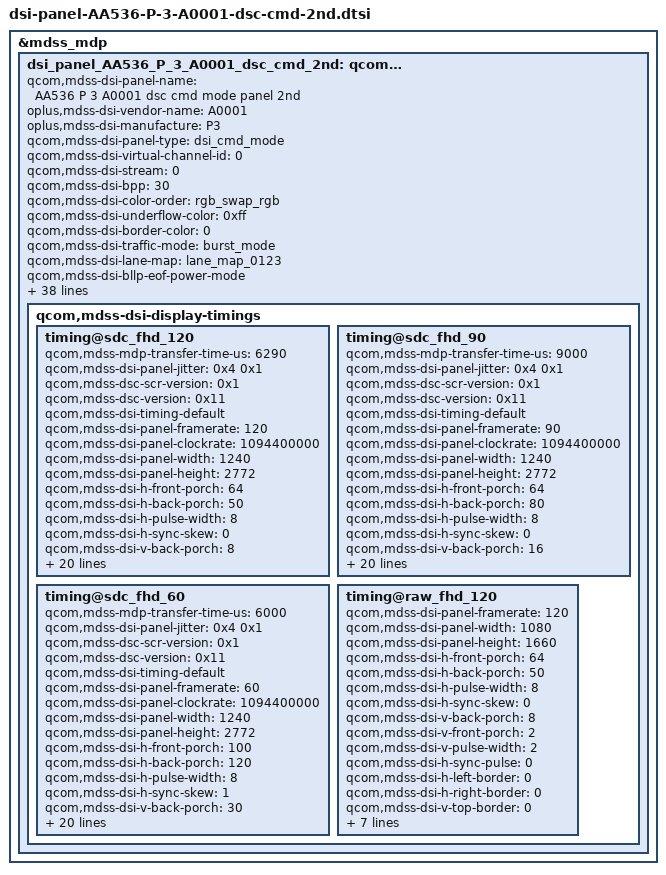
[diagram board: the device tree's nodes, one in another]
&mdss_mdp {
	dsi_panel_AA536_P_3_A0001_dsc_cmd_2nd: qcom,mdss_dsi_panel_AA536_P_3_A0001_dsc_cmd_2nd {
		qcom,mdss-dsi-panel-name = "AA536 P 3 A0001 dsc cmd mode panel 2nd";
		oplus,mdss-dsi-vendor-name = "A0001";
		oplus,mdss-dsi-manufacture = "P3";
		qcom,mdss-dsi-panel-type = "dsi_cmd_mode";
		qcom,mdss-dsi-virtual-channel-id = <0>;
		qcom,mdss-dsi-stream = <0>;
		qcom,mdss-dsi-bpp = <30>;
		qcom,mdss-dsi-color-order = "rgb_swap_rgb";
		qcom,mdss-dsi-underflow-color = <0xff>;
		qcom,mdss-dsi-border-color = <0>;
		//qcom,dsi-ctrl-num = <0>;
		//qcom,dsi-phy-num = <0>;
		qcom,mdss-dsi-traffic-mode = "burst_mode";
		qcom,mdss-dsi-lane-map = "lane_map_0123";
		qcom,mdss-dsi-bllp-eof-power-mode;
		qcom,mdss-dsi-bllp-power-mode;
		qcom,mdss-dsi-lane-0-state;
		qcom,mdss-dsi-lane-1-state;
		qcom,mdss-dsi-lane-2-state;
		qcom,mdss-dsi-lane-3-state;
		qcom,mdss-dsi-dma-trigger = "trigger_sw";
		qcom,mdss-loading-effect;
		qcom,mdss-dsi-mdp-trigger = "none";
		qcom,mdss-dsi-reset-sequence = <1 2>, <0 5>, <1 10>;
		qcom,mdss-dsi-te-pin-select = <1>;
		qcom,mdss-dsi-te-dcs-command = <1>;
		qcom,mdss-pan-physical-width-dimension = <70>;
		qcom,mdss-pan-physical-height-dimension = <155>;
		qcom,mdss-dsi-init-delay-us = <1000>;
		qcom,mdss-dsi-te-check-enable;
		qcom,mdss-dsi-te-using-te-pin;
		qcom,mdss-dsi-lp11-init;
		qcom,mdss-dsi-wr-mem-start = <0x2c>;
		qcom,mdss-dsi-wr-mem-continue = <0x3c>;
		qcom,mdss-dsi-panel-jitter = <0x4 0x1>;
		qcom,mdss-bl-high2bit;
		/* HDR Setting */
		qcom,mdss-dsi-panel-hdr-enabled;
		qcom,mdss-dsi-panel-hdr-color-primaries = <15635 16450 34000 16000 13250 34500 7500 3000>;
		qcom,mdss-dsi-panel-peak-brightness = <5400000>;
		qcom,mdss-dsi-panel-average-brightness = <2000000>;
		qcom,mdss-dsi-panel-blackness-level = <4000>;

		qcom,dynamic-mode-switch-enabled;
		qcom,dynamic-mode-switch-type = "dynamic-resolution-switch-immediate";
		qcom,mdss-dsi-display-timings {
			timing@sdc_fhd_120{
				qcom,mdss-mdp-transfer-time-us = <6290>;
				qcom,mdss-dsi-panel-jitter = <0x4 0x1>;
				qcom,mdss-dsc-scr-version = <0x1>;
				qcom,mdss-dsc-version = <0x11>;
				qcom,mdss-dsi-timing-default;
				qcom,mdss-dsi-panel-framerate = <120>;
				qcom,mdss-dsi-panel-clockrate = <1094400000>;
				qcom,mdss-dsi-panel-width = <1240>;
				qcom,mdss-dsi-panel-height = <2772>;

				qcom,mdss-dsi-h-front-porch = <64>;
				qcom,mdss-dsi-h-back-porch = <50>;
				qcom,mdss-dsi-h-pulse-width = <8>;
				qcom,mdss-dsi-h-sync-skew = <0>;
				qcom,mdss-dsi-v-back-porch = <8>;
				qcom,mdss-dsi-v-front-porch = <2>;
				qcom,mdss-dsi-v-pulse-width = <2>;
				qcom,mdss-dsi-h-sync-pulse = <0>;

				qcom,mdss-dsi-h-left-border = <0>;
				qcom,mdss-dsi-h-right-border = <0>;
				qcom,mdss-dsi-v-top-border = <0>;
				qcom,mdss-dsi-v-bottom-border = <0>;

				qcom,lm-split = <620 620>;
				qcom,compression-mode = "dsc";
				qcom,mdss-dsc-encoders = <2>;
				qcom,mdss-dsc-slice-height = <44>;
				qcom,mdss-dsc-slice-width = <620>;
				qcom,mdss-dsc-slice-per-pkt = <2>;
				qcom,mdss-dsc-bit-per-component = <10>;
				qcom,mdss-dsc-bit-per-pixel = <8>;
				qcom,mdss-dsc-block-prediction-enable;
			};
			timing@sdc_fhd_90{
				qcom,mdss-mdp-transfer-time-us = <9000>;
				qcom,mdss-dsi-panel-jitter = <0x4 0x1>;
				qcom,mdss-dsc-scr-version = <0x1>;
				qcom,mdss-dsc-version = <0x11>;
				qcom,mdss-dsi-timing-default;
				qcom,mdss-dsi-panel-framerate = <90>;
				qcom,mdss-dsi-panel-clockrate = <1094400000>;
				qcom,mdss-dsi-panel-width = <1240>;
				qcom,mdss-dsi-panel-height = <2772>;

				qcom,mdss-dsi-h-front-porch = <64>;
				qcom,mdss-dsi-h-back-porch = <80>;
				qcom,mdss-dsi-h-pulse-width = <8>;
				qcom,mdss-dsi-h-sync-skew = <0>;
				qcom,mdss-dsi-v-back-porch = <16>;
				qcom,mdss-dsi-v-front-porch = <10>;
				qcom,mdss-dsi-v-pulse-width = <2>;
				qcom,mdss-dsi-h-sync-pulse = <0>;

				qcom,mdss-dsi-h-left-border = <0>;
				qcom,mdss-dsi-h-right-border = <0>;
				qcom,mdss-dsi-v-top-border = <0>;
				qcom,mdss-dsi-v-bottom-border = <0>;

				qcom,lm-split = <620 620>;
				qcom,compression-mode = "dsc";
				qcom,mdss-dsc-encoders = <2>;
				qcom,mdss-dsc-slice-height = <44>;
				qcom,mdss-dsc-slice-width = <620>;
				qcom,mdss-dsc-slice-per-pkt = <2>;
				qcom,mdss-dsc-bit-per-component = <10>;
				qcom,mdss-dsc-bit-per-pixel = <8>;
				qcom,mdss-dsc-block-prediction-enable;
			};
			timing@sdc_fhd_60{
				qcom,mdss-mdp-transfer-time-us = <6000>;
				qcom,mdss-dsi-panel-jitter = <0x4 0x1>;
				qcom,mdss-dsc-scr-version = <0x1>;
				qcom,mdss-dsc-version = <0x11>;
				qcom,mdss-dsi-timing-default;
				qcom,mdss-dsi-panel-framerate = <60>;
				qcom,mdss-dsi-panel-clockrate = <1094400000>;
				qcom,mdss-dsi-panel-width = <1240>;
				qcom,mdss-dsi-panel-height = <2772>;

				qcom,mdss-dsi-h-front-porch = <100>;
				qcom,mdss-dsi-h-back-porch = <120>;
				qcom,mdss-dsi-h-pulse-width = <8>;
				qcom,mdss-dsi-h-sync-skew = <1>;
				qcom,mdss-dsi-v-back-porch = <30>;
				qcom,mdss-dsi-v-front-porch = <20>;
				qcom,mdss-dsi-v-pulse-width = <2>;
				qcom,mdss-dsi-h-sync-pulse = <0>;

				qcom,mdss-dsi-h-left-border = <0>;
				qcom,mdss-dsi-h-right-border = <0>;
				qcom,mdss-dsi-v-top-border = <0>;
				qcom,mdss-dsi-v-bottom-border = <0>;

				qcom,lm-split = <620 620>;
				qcom,compression-mode = "dsc";
				qcom,mdss-dsc-encoders = <2>;
				qcom,mdss-dsc-slice-height = <44>;
				qcom,mdss-dsc-slice-width = <620>;
				qcom,mdss-dsc-slice-per-pkt = <2>;
				qcom,mdss-dsc-bit-per-component = <10>;
				qcom,mdss-dsc-bit-per-pixel = <8>;
				qcom,mdss-dsc-block-prediction-enable;
			};
			timing@raw_fhd_120 {
				qcom,mdss-dsi-panel-framerate = <120>;
				//qcom,mdss-dsi-panel-clockrate = <1320000000>;
				qcom,mdss-dsi-panel-width = <1080>;
				qcom,mdss-dsi-panel-height = <1660>;

				qcom,mdss-dsi-h-front-porch = <64>;
				qcom,mdss-dsi-h-back-porch = <50>;
				qcom,mdss-dsi-h-pulse-width = <8>;
				qcom,mdss-dsi-h-sync-skew = <0>;
				qcom,mdss-dsi-v-back-porch = <8>;
				qcom,mdss-dsi-v-front-porch = <2>;
				qcom,mdss-dsi-v-pulse-width = <2>;
				qcom,mdss-dsi-h-sync-pulse = <0>;

				qcom,mdss-dsi-h-left-border = <0>;
				qcom,mdss-dsi-h-right-border = <0>;
				qcom,mdss-dsi-v-top-border = <0>;
				qcom,mdss-dsi-v-bottom-border = <0>;
			};
		};
	};
};

&dsi_panel_AA536_P_3_A0001_dsc_cmd_2nd {
	qcom,mdss-dsi-sec-bl-pmic-control-type = "bl_ctrl_external";
	qcom,mdss-dsi-bl-min-level = <1>;
	qcom,mdss-dsi-bl-max-level = <4095>;
	qcom,mdss-brightness-max-level = <4095>;


	qcom,mdss-dsi-bl-inverted-dbv;
	qcom,ulps-enabled;

	qcom,mdss-dsi-display-timings {
		timing@sdc_fhd_120 { /* FHD+ 120hz 1094.4Mbps */
			qcom,mdss-dsi-panel-phy-timings = [00 25 09 0A 1A 25 09 0A 09 02 04 00 1E 0F];
			qcom,display-topology = <1 1 1>,<2 2 1>;
			qcom,default-topology-index = <1>;
		};
		timing@sdc_fhd_90 { /* FHD+ 90hz 1094.4Mbps */
			qcom,mdss-dsi-panel-phy-timings = [00 25 09 0A 1A 25 09 0A 09 02 04 00 1E 0F];
			qcom,display-topology = <1 1 1>,<2 2 1>;
			qcom,default-topology-index = <1>;
		};
		timing@sdc_fhd_60 { /* FHD+ 60hz 1094.4Mbps */
			qcom,mdss-dsi-panel-phy-timings = [00 25 09 0A 1A 25 09 0A 09 02 04 00 1E 0F];
			qcom,display-topology = <1 1 1>,<2 2 1>;
			qcom,default-topology-index = <1>;
		};
		timing@raw_fhd_120 {
			qcom,mdss-dsi-panel-clockrate = <1440000000>;
			qcom,mdss-mdp-transfer-time-us = <6800>;  //same as main panel
			qcom,mdss-dsi-panel-phy-timings = [00 2E 0C 0C 1D 1B 0C 0D 0B 02 04 00 25 11];
			qcom,display-topology = <1 0 1>,<2 0 1>;
			qcom,default-topology-index = <1>;
		};
	};
};
